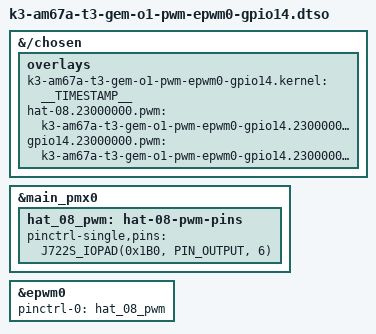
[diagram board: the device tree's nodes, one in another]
// SPDX-License-Identifier: GPL-2.0-only OR MIT
/*
 * DT Overlay to use GPIO14 (PWM1) within the expansion header for EPWM0 (pwmchip3).
 *
 * Copyright (C) 2023 Texas Instruments Incorporated - https://www.ti.com/
 */

/dts-v1/;
/plugin/;

#include <dt-bindings/gpio/gpio.h>
#include "k3-pinctrl.h"

/*
 * Helper to show loaded overlays under: /proc/device-tree/chosen/overlays/
*/
&{/chosen} {
	overlays {
		k3-am67a-t3-gem-o1-pwm-epwm0-gpio14.kernel = __TIMESTAMP__;
		hat-08.23000000.pwm = "k3-am67a-t3-gem-o1-pwm-epwm0-gpio14.23000000.1.GPIO14";
		gpio14.23000000.pwm = "k3-am67a-t3-gem-o1-pwm-epwm0-gpio14.23000000.1.GPIO14";
	};
};

&main_pmx0 {
	hat_08_pwm: hat-08-pwm-pins {
		pinctrl-single,pins = <
			J722S_IOPAD(0x1B0, PIN_OUTPUT, 6) /* (F24) MCASP0_ACLKR.EHRPWM0_B */
		>;
	};
};

&epwm0 {
	pinctrl-names = "default";
	pinctrl-0 = <&hat_08_pwm>;
	status = "okay";
};
